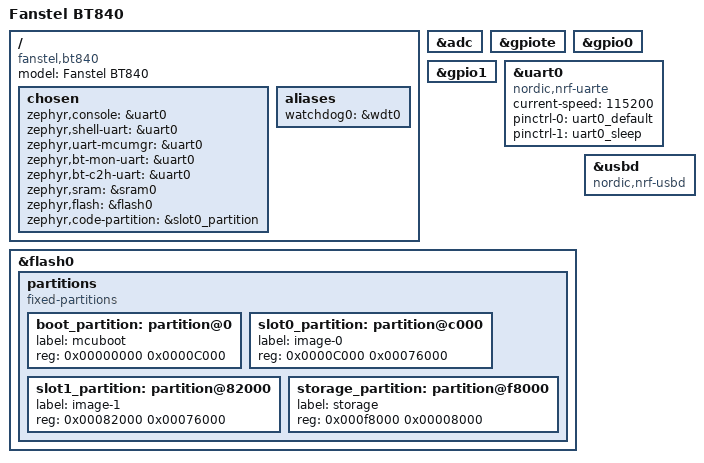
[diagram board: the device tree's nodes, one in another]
/*
 * Copyright (c) 2024 RedNodeLabs.
 *
 * SPDX-License-Identifier: Apache-2.0
 */

/dts-v1/;
#include <nordic/nrf52840_qiaa.dtsi>
#include "fanstel_bt840-pinctrl.dtsi"

/ {
	model = "Fanstel BT840";
	compatible = "fanstel,bt840";

	chosen {
		zephyr,console        = &uart0;
		zephyr,shell-uart     = &uart0;
		zephyr,uart-mcumgr    = &uart0;
		zephyr,bt-mon-uart    = &uart0;
		zephyr,bt-c2h-uart    = &uart0;
		zephyr,sram           = &sram0;
		zephyr,flash          = &flash0;
		zephyr,code-partition = &slot0_partition;
	};

	/* These aliases are provided for compatibility with samples */
	aliases {
		watchdog0       = &wdt0;
	};

};

&adc {
	status = "okay";
};

&gpiote {
	status = "okay";
};

&gpio0 {
	status = "okay";
};

&gpio1 {
	status = "okay";
};

&uart0 {
	compatible = "nordic,nrf-uarte";
	status = "okay";
	current-speed = <115200>;
	pinctrl-0 = <&uart0_default>;
	pinctrl-1 = <&uart0_sleep>;
	pinctrl-names = "default", "sleep";
};

&flash0 {

	partitions {
		compatible = "fixed-partitions";
		#address-cells = <1>;
		#size-cells = <1>;

		boot_partition: partition@0 {
			label = "mcuboot";
			reg = <0x00000000 0x0000C000>;
		};
		slot0_partition: partition@c000 {
			label = "image-0";
			reg = <0x0000C000 0x00076000>;
		};
		slot1_partition: partition@82000 {
			label = "image-1";
			reg = <0x00082000 0x00076000>;
		};
		storage_partition: partition@f8000 {
			label = "storage";
			reg = <0x000f8000 0x00008000>;
		};
	};
};

zephyr_udc0: &usbd {
	compatible = "nordic,nrf-usbd";
	status = "okay";
};
